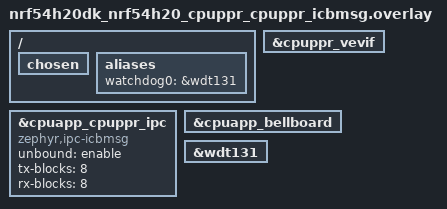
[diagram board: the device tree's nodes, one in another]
/*
 * Copyright (c) 2024 Nordic Semiconductor ASA
 * SPDX-License-Identifier: LicenseRef-Nordic-5-Clause
 */

ipc0: &cpuapp_cpuppr_ipc {
	compatible = "zephyr,ipc-icbmsg";
	status = "okay";
	unbound = "enable";
	tx-blocks = <8>;
	rx-blocks = <8>;
};

&cpuppr_vevif {
	status = "okay";
};

&cpuapp_bellboard {
	status = "okay";
};

&wdt131 {
	status = "okay";
};

/ {
	chosen {
		/delete-property/ zephyr,bt-hci;
	};

	aliases {
		watchdog0 = &wdt131;
	};
};
